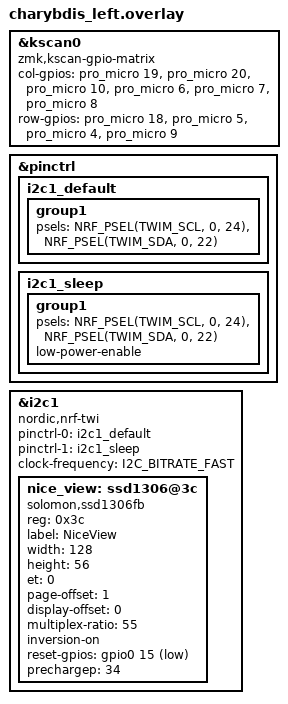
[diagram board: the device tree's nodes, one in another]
#include "charybdis.dtsi"

&kscan0 {
	compatible = "zmk,kscan-gpio-matrix";

	col-gpios
		= <&pro_micro 19 (GPIO_ACTIVE_HIGH | GPIO_PULL_DOWN)>
		, <&pro_micro 20 (GPIO_ACTIVE_HIGH | GPIO_PULL_DOWN)>
		, <&pro_micro 10 (GPIO_ACTIVE_HIGH | GPIO_PULL_DOWN)>
		, <&pro_micro 6 (GPIO_ACTIVE_HIGH | GPIO_PULL_DOWN)>
		, <&pro_micro 7 (GPIO_ACTIVE_HIGH | GPIO_PULL_DOWN)>
		, <&pro_micro 8 (GPIO_ACTIVE_HIGH | GPIO_PULL_DOWN)>
		;

	row-gpios
		= <&pro_micro 18 GPIO_ACTIVE_HIGH>
		, <&pro_micro 5 GPIO_ACTIVE_HIGH>
		, <&pro_micro 4 GPIO_ACTIVE_HIGH>
		, <&pro_micro 9 GPIO_ACTIVE_HIGH>
		;
};

&pinctrl {
    i2c1_default: i2c1_default {
        group1 {
            psels = <NRF_PSEL(TWIM_SCL, 0, 24)>, /* SCL = P0.24 */
                    <NRF_PSEL(TWIM_SDA, 0, 22)>; /* SDA = P0.22 */
        };
    };

    i2c1_sleep: i2c1_sleep {
        group1 {
            psels = <NRF_PSEL(TWIM_SCL, 0, 24)>,
                    <NRF_PSEL(TWIM_SDA, 0, 22)>;
            low-power-enable;
        };
    };
};

&i2c1 {
  compatible = "nordic,nrf-twi";
  status = "okay";
  pinctrl-0 = <&i2c1_default>;
  pinctrl-1 = <&i2c1_sleep>;
  pinctrl-names = "default", "sleep";
  clock-frequency = <I2C_BITRATE_FAST>;

  nice_view: ssd1306@3c {
    compatible = "solomon,ssd1306fb";
    reg = <0x3c>;
    label = "NiceView";
    width = <128>;
    height = <56>;
    segment-offs
    et = <0>;        /* default safe value */
    page-offset = <1>;           /* default safe value */
    display-offset = <0>;        /* vertical shift */
    multiplex-ratio = <55>;      /* (height - 1) */
    inversion-on;/* 1 = enabled, 0 = disabled */
    reset-gpios = <&gpio0 15 GPIO_ACTIVE_LOW>; /*  optional, change if wired */
    prechargep = <34>;
 };
};

